# STM32MP157 register map
File version: 1.6
CPU: CM4 r0p1, little endian, no MPU, FPU, 4 interrupt priority bits
Registers are 32-bit, read-write, reset 0x0 unless marked. A register's access mark holds for its fields unless they carry their own. Offsets are from the block's base; [hi:lo] are bit positions; {n}, {i} and the like mark numbered series; 'fields as' and 'values as' point back to an identical list.

## DDRCTRL
Base 0x5A003000
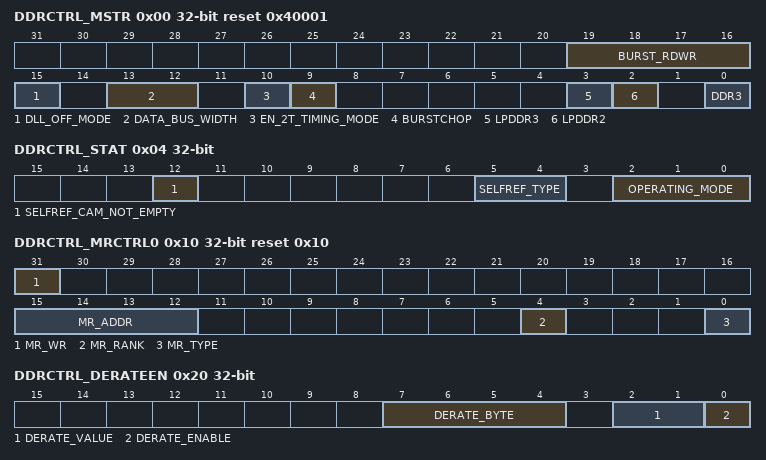
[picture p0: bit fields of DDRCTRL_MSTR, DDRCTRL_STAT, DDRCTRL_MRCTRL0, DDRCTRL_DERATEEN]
0x00 DDRCTRL_MSTR reset 0x40001 — DDRCTRL master register 0
  [19:16] BURST_RDWR, [15] DLL_OFF_MODE, [13:12] DATA_BUS_WIDTH, [10] EN_2T_TIMING_MODE, [9] BURSTCHOP, [3] LPDDR3, [2] LPDDR2, [0] DDR3
0x04 DDRCTRL_STAT ro — DDRCTRL operating mode status register
  [12] SELFREF_CAM_NOT_EMPTY, [5:4] SELFREF_TYPE, [2:0] OPERATING_MODE
0x10 DDRCTRL_MRCTRL0 reset 0x10 — Mode Register Read/Write Control Register 0. Do not enable more than one of the following fields simultaneously: sw_init_int pda_en mpr_en
  [31] MR_WR, [15:12] MR_ADDR, [4] MR_RANK, [0] MR_TYPE
0x14 DDRCTRL_MRCTRL1 — DDRCTRL mode register read/write control register 1
  [15:0] MR_DATA
0x18 DDRCTRL_MRSTAT ro — DDRCTRL mode register read/write status register
  [0] MR_WR_BUSY
0x20 DDRCTRL_DERATEEN — DDRCTRL temperature derate enable register
  [7:4] DERATE_BYTE, [2:1] DERATE_VALUE, [0] DERATE_ENABLE
0x24 DDRCTRL_DERATEINT reset 0x800000 — DDRCTRL temperature derate interval register
  [31:0] MR4_READ_INTERVAL
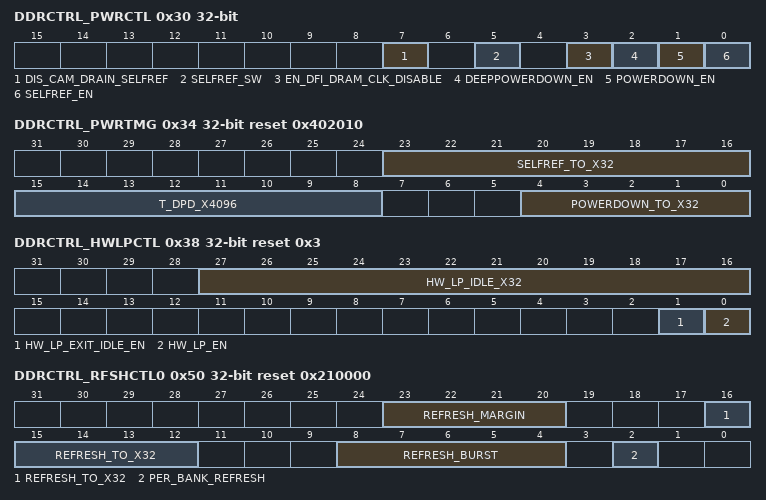
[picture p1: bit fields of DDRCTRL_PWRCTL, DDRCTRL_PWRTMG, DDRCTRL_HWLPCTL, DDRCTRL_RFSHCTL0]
0x30 DDRCTRL_PWRCTL — DDRCTRL low power control register
  [7] DIS_CAM_DRAIN_SELFREF, [5] SELFREF_SW, [3] EN_DFI_DRAM_CLK_DISABLE, [2] DEEPPOWERDOWN_EN, [1] POWERDOWN_EN, [0] SELFREF_EN
0x34 DDRCTRL_PWRTMG reset 0x402010 — DDRCTRL low power timing register
  [23:16] SELFREF_TO_X32, [15:8] T_DPD_X4096, [4:0] POWERDOWN_TO_X32
0x38 DDRCTRL_HWLPCTL reset 0x3 — DDRCTRL hardware low power control register
  [27:16] HW_LP_IDLE_X32, [1] HW_LP_EXIT_IDLE_EN, [0] HW_LP_EN
0x50 DDRCTRL_RFSHCTL0 reset 0x210000 — DDRCTRL refresh control register 0
  [23:20] REFRESH_MARGIN, [16:12] REFRESH_TO_X32, [8:4] REFRESH_BURST, [2] PER_BANK_REFRESH
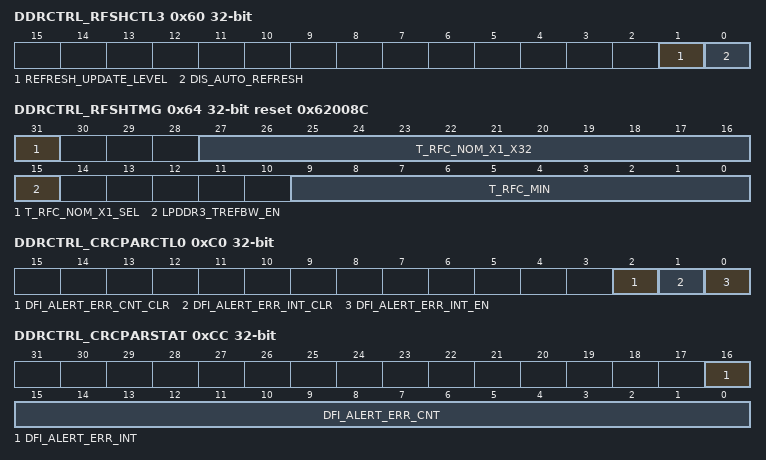
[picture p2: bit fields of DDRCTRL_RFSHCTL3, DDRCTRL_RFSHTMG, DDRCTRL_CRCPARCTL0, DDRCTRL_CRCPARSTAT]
0x60 DDRCTRL_RFSHCTL3 — DDRCTRL refresh control register 3
  [1] REFRESH_UPDATE_LEVEL, [0] DIS_AUTO_REFRESH
0x64 DDRCTRL_RFSHTMG reset 0x62008C — DDRCTRL refresh timing register
  [31] T_RFC_NOM_X1_SEL, [27:16] T_RFC_NOM_X1_X32, [15] LPDDR3_TREFBW_EN, [9:0] T_RFC_MIN
0xC0 DDRCTRL_CRCPARCTL0 — DDRCTRL CRC parity control register 0
  [2] DFI_ALERT_ERR_CNT_CLR, [1] DFI_ALERT_ERR_INT_CLR, [0] DFI_ALERT_ERR_INT_EN
0xCC DDRCTRL_CRCPARSTAT ro — DDRCTRL CRC parity status register
  [16] DFI_ALERT_ERR_INT, [15:0] DFI_ALERT_ERR_CNT
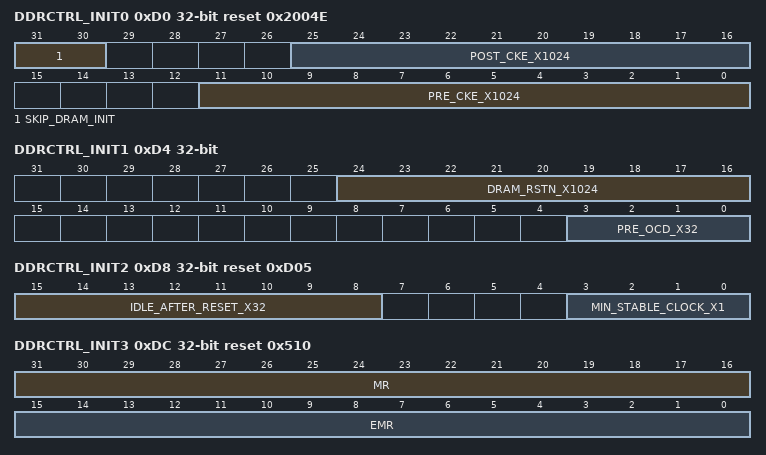
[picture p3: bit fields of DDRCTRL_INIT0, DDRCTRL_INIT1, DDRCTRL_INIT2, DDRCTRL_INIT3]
0xD0 DDRCTRL_INIT0 reset 0x2004E — DDRCTRL SDRAM initialization register 0
  [31:30] SKIP_DRAM_INIT, [25:16] POST_CKE_X1024, [11:0] PRE_CKE_X1024
0xD4 DDRCTRL_INIT1 — DDRCTRL SDRAM initialization register 1
  [24:16] DRAM_RSTN_X1024, [3:0] PRE_OCD_X32
0xD8 DDRCTRL_INIT2 reset 0xD05 — DDRCTRL SDRAM initialization register 2
  [15:8] IDLE_AFTER_RESET_X32, [3:0] MIN_STABLE_CLOCK_X1
0xDC DDRCTRL_INIT3 reset 0x510 — DDRCTRL SDRAM initialization register 3
  [31:16] MR, [15:0] EMR
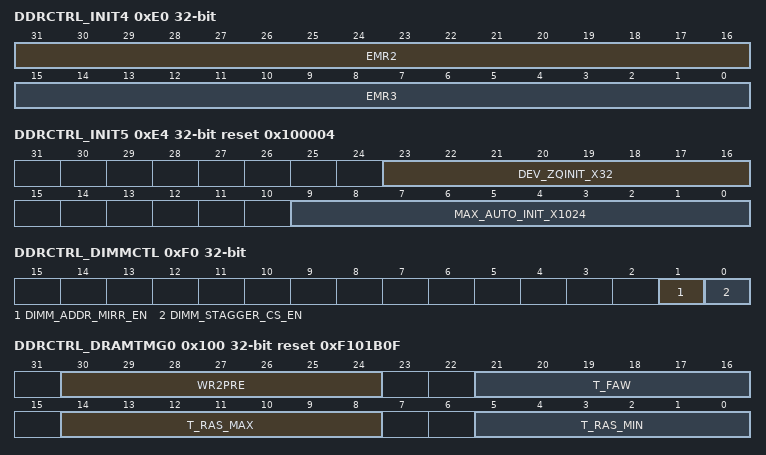
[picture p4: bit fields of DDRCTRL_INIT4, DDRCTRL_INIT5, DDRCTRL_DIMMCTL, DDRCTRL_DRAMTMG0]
0xE0 DDRCTRL_INIT4 — DDRCTRL SDRAM initialization register 4
  [31:16] EMR2, [15:0] EMR3
0xE4 DDRCTRL_INIT5 reset 0x100004 — DDRCTRL SDRAM initialization register 5
  [23:16] DEV_ZQINIT_X32, [9:0] MAX_AUTO_INIT_X1024
0xF0 DDRCTRL_DIMMCTL — DDRCTRL DIMM control register
  [1] DIMM_ADDR_MIRR_EN, [0] DIMM_STAGGER_CS_EN
0x100 DDRCTRL_DRAMTMG0 reset 0xF101B0F — DDRCTRL SDRAM timing register 0
  [30:24] WR2PRE, [21:16] T_FAW, [14:8] T_RAS_MAX, [5:0] T_RAS_MIN
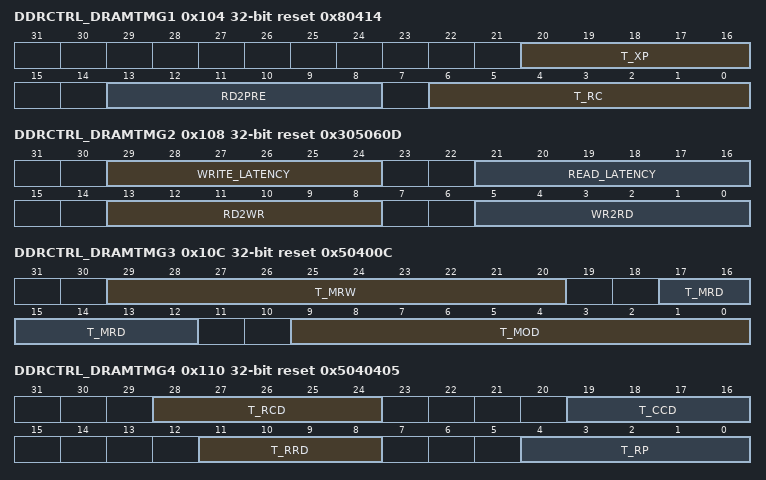
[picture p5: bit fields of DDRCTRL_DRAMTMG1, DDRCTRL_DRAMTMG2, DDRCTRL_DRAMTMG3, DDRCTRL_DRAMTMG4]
0x104 DDRCTRL_DRAMTMG1 reset 0x80414 — DDRCTRL SDRAM timing register 1
  [20:16] T_XP, [13:8] RD2PRE, [6:0] T_RC
0x108 DDRCTRL_DRAMTMG2 reset 0x305060D — DDRCTRL SDRAM timing register 2
  [29:24] WRITE_LATENCY, [21:16] READ_LATENCY, [13:8] RD2WR, [5:0] WR2RD
0x10C DDRCTRL_DRAMTMG3 reset 0x50400C — DDRCTRL SDRAM timing register 3
  [29:20] T_MRW, [17:12] T_MRD, [9:0] T_MOD
0x110 DDRCTRL_DRAMTMG4 reset 0x5040405 — DDRCTRL SDRAM timing register 4
  [28:24] T_RCD, [19:16] T_CCD, [11:8] T_RRD, [4:0] T_RP
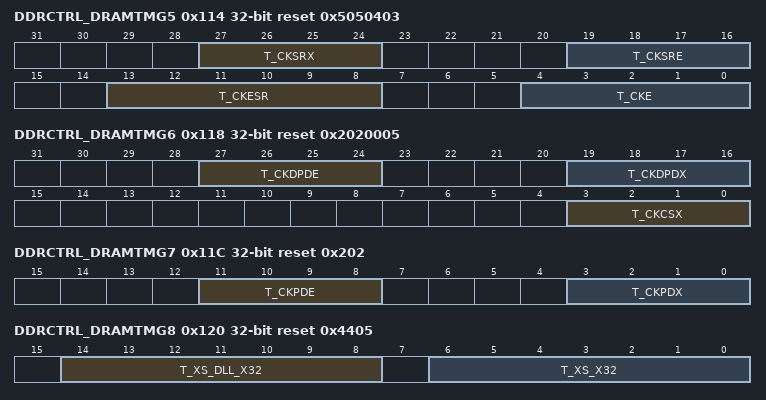
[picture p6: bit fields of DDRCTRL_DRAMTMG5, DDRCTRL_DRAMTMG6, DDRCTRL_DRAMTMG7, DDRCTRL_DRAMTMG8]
0x114 DDRCTRL_DRAMTMG5 reset 0x5050403 — DDRCTRL SDRAM timing register 5
  [27:24] T_CKSRX, [19:16] T_CKSRE, [13:8] T_CKESR, [4:0] T_CKE
0x118 DDRCTRL_DRAMTMG6 reset 0x2020005 — DDRCTRL SDRAM timing register 6
  [27:24] T_CKDPDE, [19:16] T_CKDPDX, [3:0] T_CKCSX
0x11C DDRCTRL_DRAMTMG7 reset 0x202 — DDRCTRL SDRAM timing register 7
  [11:8] T_CKPDE, [3:0] T_CKPDX
0x120 DDRCTRL_DRAMTMG8 reset 0x4405 — DDRCTRL SDRAM timing register 8
  [14:8] T_XS_DLL_X32, [6:0] T_XS_X32
0x138 DDRCTRL_DRAMTMG14 reset 0xA0 — DDRCTRL SDRAM timing register 14
  [11:0] T_XSR
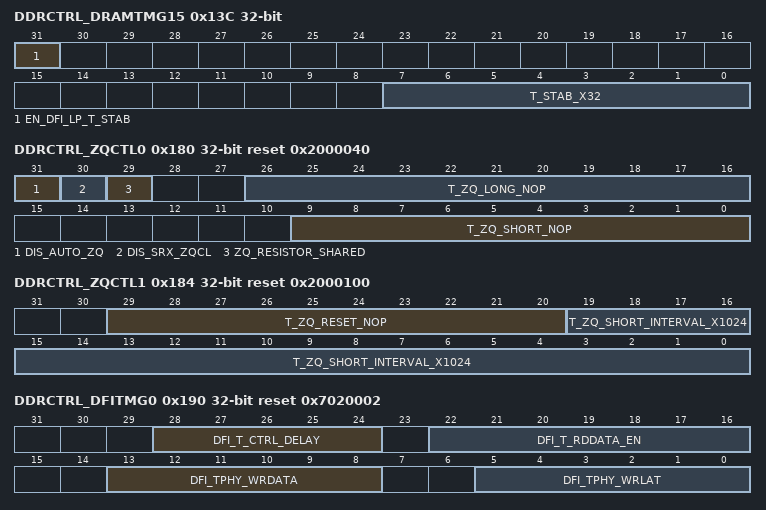
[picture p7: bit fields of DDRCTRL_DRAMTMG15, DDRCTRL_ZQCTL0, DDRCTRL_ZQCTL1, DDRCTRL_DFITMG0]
0x13C DDRCTRL_DRAMTMG15 — DDRCTRL SDRAM timing register 15
  [31] EN_DFI_LP_T_STAB, [7:0] T_STAB_X32
0x180 DDRCTRL_ZQCTL0 reset 0x2000040 — DDRCTRL ZQ control register 0
  [31] DIS_AUTO_ZQ, [30] DIS_SRX_ZQCL, [29] ZQ_RESISTOR_SHARED, [26:16] T_ZQ_LONG_NOP, [9:0] T_ZQ_SHORT_NOP
0x184 DDRCTRL_ZQCTL1 reset 0x2000100 — DDRCTRL ZQ control register 1
  [29:20] T_ZQ_RESET_NOP, [19:0] T_ZQ_SHORT_INTERVAL_X1024
0x188 DDRCTRL_ZQCTL2 — DDRCTRL ZQ control register 2
  [0] ZQ_RESET
0x18C DDRCTRL_ZQSTAT ro — DDRCTRL ZQ status register
  [0] ZQ_RESET_BUSY
0x190 DDRCTRL_DFITMG0 reset 0x7020002 — DDRCTRL DFI timing register 0
  [28:24] DFI_T_CTRL_DELAY, [22:16] DFI_T_RDDATA_EN, [13:8] DFI_TPHY_WRDATA, [5:0] DFI_TPHY_WRLAT
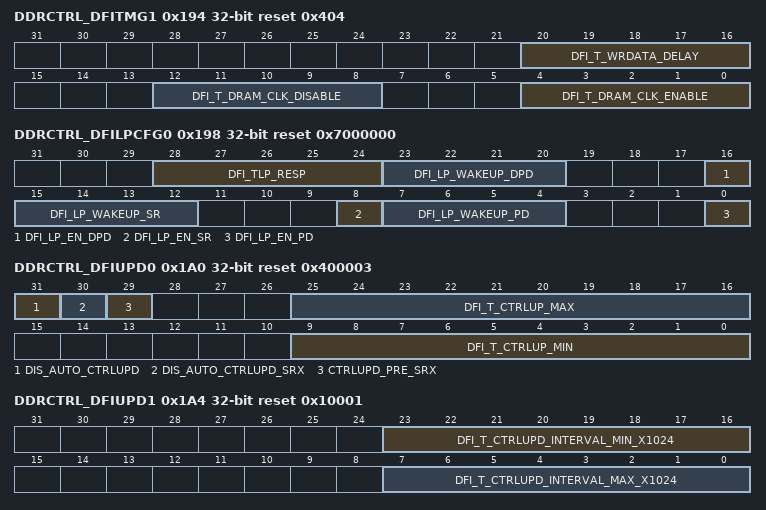
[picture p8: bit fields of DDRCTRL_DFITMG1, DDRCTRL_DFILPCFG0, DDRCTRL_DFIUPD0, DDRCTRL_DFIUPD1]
0x194 DDRCTRL_DFITMG1 reset 0x404 — DDRCTRL DFI timing register 1
  [20:16] DFI_T_WRDATA_DELAY, [12:8] DFI_T_DRAM_CLK_DISABLE, [4:0] DFI_T_DRAM_CLK_ENABLE
0x198 DDRCTRL_DFILPCFG0 reset 0x7000000 — DDRCTRL low power configuration register 0
  [28:24] DFI_TLP_RESP, [23:20] DFI_LP_WAKEUP_DPD, [16] DFI_LP_EN_DPD, [15:12] DFI_LP_WAKEUP_SR, [8] DFI_LP_EN_SR, [7:4] DFI_LP_WAKEUP_PD, [0] DFI_LP_EN_PD
0x1A0 DDRCTRL_DFIUPD0 reset 0x400003 — DDRCTRL DFI update register 0
  [31] DIS_AUTO_CTRLUPD, [30] DIS_AUTO_CTRLUPD_SRX, [29] CTRLUPD_PRE_SRX, [25:16] DFI_T_CTRLUP_MAX, [9:0] DFI_T_CTRLUP_MIN
0x1A4 DDRCTRL_DFIUPD1 reset 0x10001 — DDRCTRL DFI update register 1
  [23:16] DFI_T_CTRLUPD_INTERVAL_MIN_X1024, [7:0] DFI_T_CTRLUPD_INTERVAL_MAX_X1024
0x1A8 DDRCTRL_DFIUPD2 reset 0x80000000 — DDRCTRL DFI update register 2
  [31] DFI_PHYUPD_EN
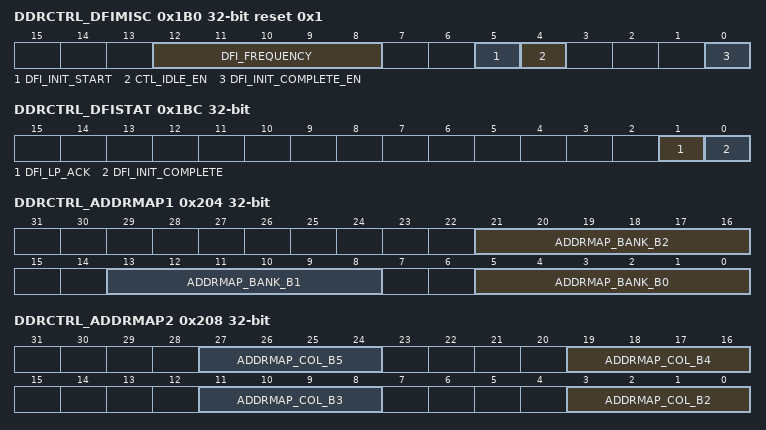
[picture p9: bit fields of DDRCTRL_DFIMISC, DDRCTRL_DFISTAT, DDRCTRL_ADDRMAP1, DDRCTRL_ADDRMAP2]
0x1B0 DDRCTRL_DFIMISC reset 0x1 — DDRCTRL DFI miscellaneous control register
  [12:8] DFI_FREQUENCY, [5] DFI_INIT_START, [4] CTL_IDLE_EN, [0] DFI_INIT_COMPLETE_EN
0x1BC DDRCTRL_DFISTAT ro — DDRCTRL DFI status register
  [1] DFI_LP_ACK, [0] DFI_INIT_COMPLETE
0x1C4 DDRCTRL_DFIPHYMSTR reset 0x1 — DDRCTRL DFI PHY master register
  [0] DFI_PHYMSTR_EN
0x204 DDRCTRL_ADDRMAP1 — DDRCTRL address map register 1
  [21:16] ADDRMAP_BANK_B2, [13:8] ADDRMAP_BANK_B1, [5:0] ADDRMAP_BANK_B0
0x208 DDRCTRL_ADDRMAP2 — DDRCTRL address map register 2
  [8n-13:8n-16] ADDRMAP_COL_B{n} (n=2..5)
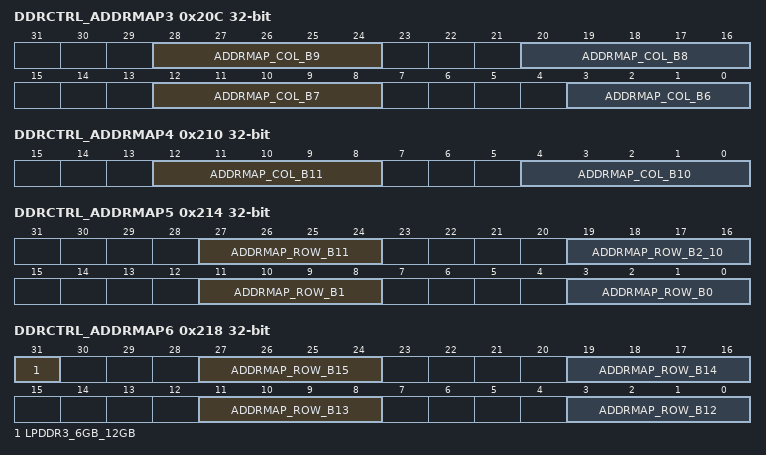
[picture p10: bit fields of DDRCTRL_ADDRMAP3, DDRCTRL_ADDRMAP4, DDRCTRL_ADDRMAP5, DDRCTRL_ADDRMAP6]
0x20C DDRCTRL_ADDRMAP3 — DDRCTRL address map register 3
  [28:24] ADDRMAP_COL_B9, [20:16] ADDRMAP_COL_B8, [12:8] ADDRMAP_COL_B7, [3:0] ADDRMAP_COL_B6
0x210 DDRCTRL_ADDRMAP4 — DDRCTRL address map register 4
  [12:8] ADDRMAP_COL_B11, [4:0] ADDRMAP_COL_B10
0x214 DDRCTRL_ADDRMAP5 — DDRCTRL address map register 5
  [27:24] ADDRMAP_ROW_B11, [19:16] ADDRMAP_ROW_B2_10, [11:8] ADDRMAP_ROW_B1, [3:0] ADDRMAP_ROW_B0
0x218 DDRCTRL_ADDRMAP6 — DDRCTRL address register 6
  [31] LPDDR3_6GB_12GB, [8n-93:8n-96] ADDRMAP_ROW_B{n} (n=12..15)
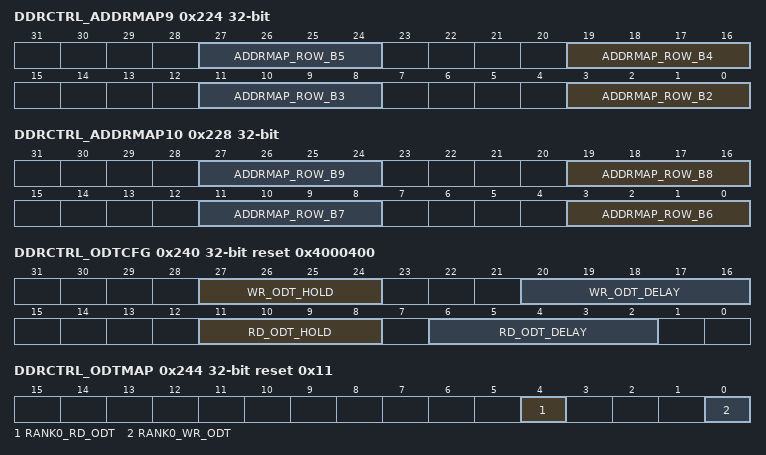
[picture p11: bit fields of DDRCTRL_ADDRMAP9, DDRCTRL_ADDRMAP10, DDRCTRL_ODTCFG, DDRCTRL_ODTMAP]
0x224 DDRCTRL_ADDRMAP9 — DDRCTRL address map register 9
  [8n-13:8n-16] ADDRMAP_ROW_B{n} (n=2..5)
0x228 DDRCTRL_ADDRMAP10 — DDRCTRL address map register 10
  [8n-45:8n-48] ADDRMAP_ROW_B{n} (n=6..9)
0x22C DDRCTRL_ADDRMAP11 — DDRCTRL address map register 11
  [3:0] ADDRMAP_ROW_B10
0x240 DDRCTRL_ODTCFG reset 0x4000400 — DDRCTRL ODT configuration register
  [27:24] WR_ODT_HOLD, [20:16] WR_ODT_DELAY, [11:8] RD_ODT_HOLD, [6:2] RD_ODT_DELAY
0x244 DDRCTRL_ODTMAP reset 0x11 — DDRCTRL ODT/Rank map register
  [4] RANK0_RD_ODT, [0] RANK0_WR_ODT
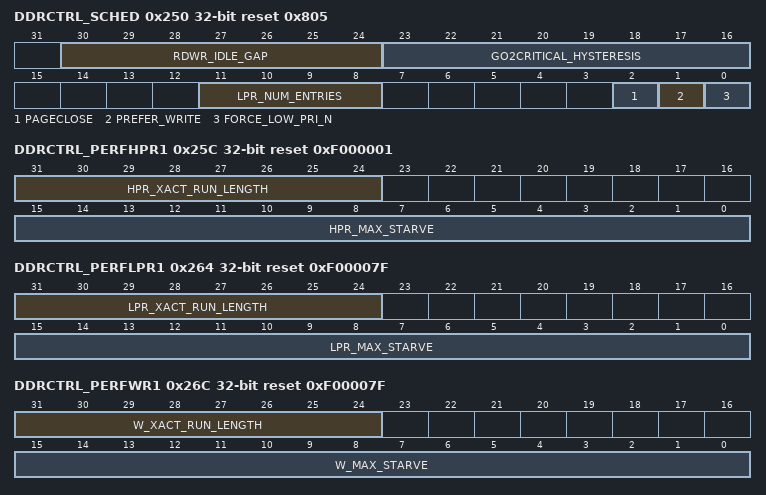
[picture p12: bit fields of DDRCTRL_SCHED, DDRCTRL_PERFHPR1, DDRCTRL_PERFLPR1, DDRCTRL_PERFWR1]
0x250 DDRCTRL_SCHED reset 0x805 — DDRCTRL scheduler control register
  [30:24] RDWR_IDLE_GAP, [23:16] GO2CRITICAL_HYSTERESIS, [11:8] LPR_NUM_ENTRIES, [2] PAGECLOSE, [1] PREFER_WRITE, [0] FORCE_LOW_PRI_N
0x254 DDRCTRL_SCHED1 — DDRCTRL scheduler control register 1
  [7:0] PAGECLOSE_TIMER
0x25C DDRCTRL_PERFHPR1 reset 0xF000001 — DDRCTRL high priority read CAM register 1
  [31:24] HPR_XACT_RUN_LENGTH, [15:0] HPR_MAX_STARVE
0x264 DDRCTRL_PERFLPR1 reset 0xF00007F — DDRCTRL low priority read CAM register 1
  [31:24] LPR_XACT_RUN_LENGTH, [15:0] LPR_MAX_STARVE
0x26C DDRCTRL_PERFWR1 reset 0xF00007F — DDRCTRL write CAM register 1
  [31:24] W_XACT_RUN_LENGTH, [15:0] W_MAX_STARVE
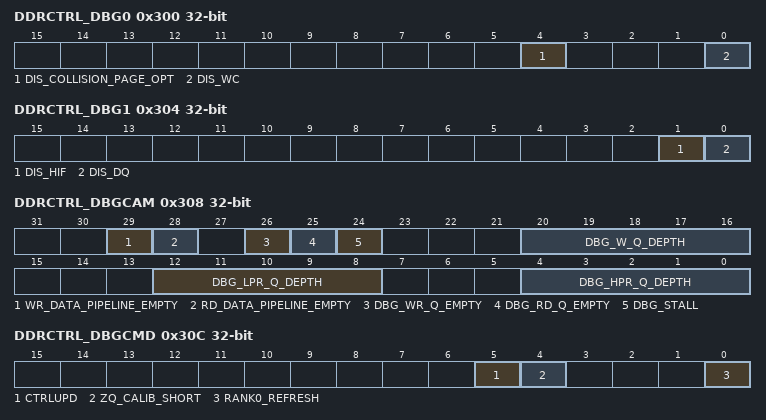
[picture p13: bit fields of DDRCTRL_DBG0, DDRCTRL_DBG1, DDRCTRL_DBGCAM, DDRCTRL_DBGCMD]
0x300 DDRCTRL_DBG0 — DDRCTRL debug register 0
  [4] DIS_COLLISION_PAGE_OPT, [0] DIS_WC
0x304 DDRCTRL_DBG1 — DDRCTRL debug register 1
  [1] DIS_HIF, [0] DIS_DQ
0x308 DDRCTRL_DBGCAM ro — DDRCTRL CAM debug register
  [29] WR_DATA_PIPELINE_EMPTY, [28] RD_DATA_PIPELINE_EMPTY, [26] DBG_WR_Q_EMPTY, [25] DBG_RD_Q_EMPTY, [24] DBG_STALL, [20:16] DBG_W_Q_DEPTH, [12:8] DBG_LPR_Q_DEPTH, [4:0] DBG_HPR_Q_DEPTH
0x30C DDRCTRL_DBGCMD — DDRCTRL command debug register
  [5] CTRLUPD, [4] ZQ_CALIB_SHORT, [0] RANK0_REFRESH
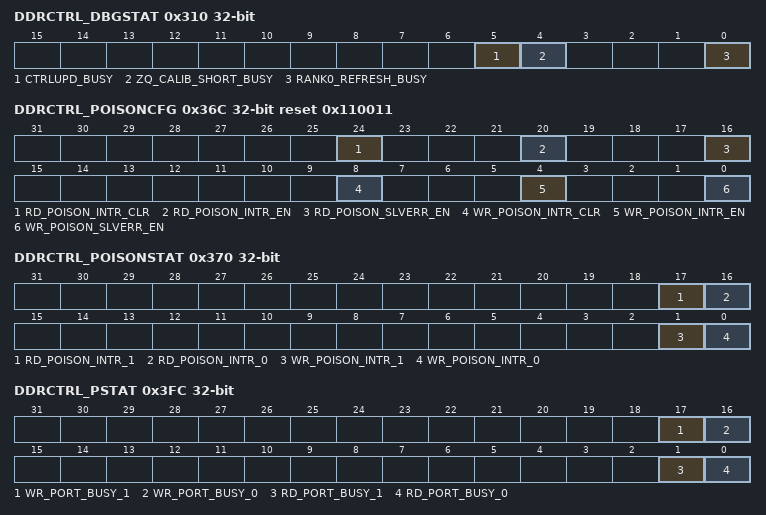
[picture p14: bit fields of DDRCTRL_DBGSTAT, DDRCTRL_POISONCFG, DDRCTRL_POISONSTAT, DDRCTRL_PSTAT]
0x310 DDRCTRL_DBGSTAT ro — DDRCTRL status debug register
  [5] CTRLUPD_BUSY, [4] ZQ_CALIB_SHORT_BUSY, [0] RANK0_REFRESH_BUSY
0x320 DDRCTRL_SWCTL reset 0x1 — DDRCTRL software register programming control enable
  [0] SW_DONE
0x324 DDRCTRL_SWSTAT ro reset 0x1 — DDRCTRL software register programming control status
  [0] SW_DONE_ACK
0x36C DDRCTRL_POISONCFG reset 0x110011 — AXI Poison configuration register common for all AXI ports.
  [24] RD_POISON_INTR_CLR, [20] RD_POISON_INTR_EN, [16] RD_POISON_SLVERR_EN, [8] WR_POISON_INTR_CLR, [4] WR_POISON_INTR_EN, [0] WR_POISON_SLVERR_EN
0x370 DDRCTRL_POISONSTAT ro — DDRCTRL AXI Poison status register
  [17] RD_POISON_INTR_1, [16] RD_POISON_INTR_0, [1] WR_POISON_INTR_1, [0] WR_POISON_INTR_0
0x3FC DDRCTRL_PSTAT ro — DDRCTRL port status register
  [17] WR_PORT_BUSY_1, [16] WR_PORT_BUSY_0, [1] RD_PORT_BUSY_1, [0] RD_PORT_BUSY_0
0x400 DDRCTRL_PCCFG — DDRCTRL port common configuration register
  [8] BL_EXP_MODE, [4] PAGEMATCH_LIMIT, [0] GO2CRITICAL_EN
0x404 DDRCTRL_PCFGR_0 reset 0x4000 — DDRCTRL port 0 configuration read register
  [16] RDWR_ORDERED_EN, [14] RD_PORT_PAGEMATCH_EN, [13] RD_PORT_URGENT_EN, [12] RD_PORT_AGING_EN, [9:0] RD_PORT_PRIORITY
0x408 DDRCTRL_PCFGW_0 reset 0x4000 — DDRCTRL port 0 configuration write register
  [14] WR_PORT_PAGEMATCH_EN, [13] WR_PORT_URGENT_EN, [12] WR_PORT_AGING_EN, [9:0] WR_PORT_PRIORITY
0x490 DDRCTRL_PCTRL_0 — DDRCTRL port 0 control register
  [0] PORT_EN
0x494 DDRCTRL_PCFGQOS0_0 reset 0x2000E00 — DDRCTRL port 0 read Q0S configuration register 0
  [25:24] RQOS_MAP_REGION2, [21:20] RQOS_MAP_REGION1, [17:16] RQOS_MAP_REGION0, [11:8] RQOS_MAP_LEVEL2, [3:0] RQOS_MAP_LEVEL1
0x498 DDRCTRL_PCFGQOS1_0 — DDRCTRL port 0 read Q0S configuration register 1
  [26:16] RQOS_MAP_TIMEOUTR, [10:0] RQOS_MAP_TIMEOUTB
0x49C DDRCTRL_PCFGWQOS0_0 reset 0xE00 — DDRCTRL port 0 write Q0S configuration register 0
  [25:24] WQOS_MAP_REGION2, [21:20] WQOS_MAP_REGION1, [17:16] WQOS_MAP_REGION0, [11:8] WQOS_MAP_LEVEL2, [3:0] WQOS_MAP_LEVEL1
0x4A0 DDRCTRL_PCFGWQOS1_0 — DDRCTRL port 0 write Q0S configuration register 1
  [26:16] WQOS_MAP_TIMEOUT2, [10:0] WQOS_MAP_TIMEOUT1
0x4B4 DDRCTRL_PCFGR_1 reset 0x4000 — DDRCTRL port 1 configuration read register
  fields as DDRCTRL_PCFGR_0
0x4B8 DDRCTRL_PCFGW_1 reset 0x4000 — DDRCTRL port 1 configuration write register
  fields as DDRCTRL_PCFGW_0
0x540 DDRCTRL_PCTRL_1 — DDRCTRL port 1 control register
  [0] PORT_EN
0x544 DDRCTRL_PCFGQOS0_1 reset 0x2000E00 — DDRCTRL port 1 read Q0S configuration register 0
  fields as DDRCTRL_PCFGQOS0_0
0x548 DDRCTRL_PCFGQOS1_1 — DDRCTRL port 1 read Q0S configuration register 1
  [26:16] RQOS_MAP_TIMEOUTR, [10:0] RQOS_MAP_TIMEOUTB
0x54C DDRCTRL_PCFGWQOS0_1 reset 0xE00 — DDRCTRL port 1 write Q0S configuration register 0
  fields as DDRCTRL_PCFGWQOS0_0
0x550 DDRCTRL_PCFGWQOS1_1 — DDRCTRL port 1 write Q0S configuration register 1
  [26:16] WQOS_MAP_TIMEOUT2, [10:0] WQOS_MAP_TIMEOUT1
